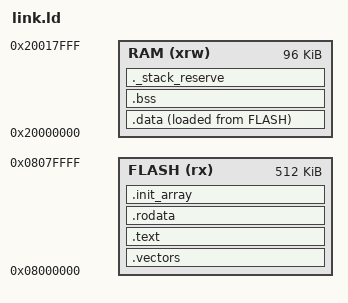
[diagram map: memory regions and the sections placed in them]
ENTRY(_reset)

_estack = ORIGIN(RAM) + LENGTH(RAM);
_Min_Stack_Size = 0x400;

MEMORY
{
  FLASH (rx)  : ORIGIN = 0x08000000, LENGTH = 512K
  RAM   (xrw) : ORIGIN = 0x20000000, LENGTH = 96K
}

SECTIONS
{
  .vectors :
  {
    . = ALIGN(4);
    KEEP(*(.vectors))
    . = ALIGN(4);
  } > FLASH

  .text :
  {
    . = ALIGN(4);
    *(.text .text*)
    *(.glue_7)
    *(.glue_7t)
    . = ALIGN(4);
    _etext = .;
  } > FLASH

  .rodata :
  {
    . = ALIGN(4);
    *(.rodata .rodata*)
    . = ALIGN(4);
  } > FLASH

  .init_array (READONLY) :
  {
    PROVIDE_HIDDEN(__init_array_start = .);
    KEEP(*(SORT(.init_array.*)))
    KEEP(*(.init_array*))
    PROVIDE_HIDDEN(__init_array_end = .);
  } > FLASH

  _sidata = LOADADDR(.data);
  .data :
  {
    . = ALIGN(4);
    _sdata = .;
    *(.data .data*)
    *(.RamFunc .RamFunc*)
    . = ALIGN(4);
    _edata = .;
  } > RAM AT > FLASH

  .bss (NOLOAD) :
  {
    . = ALIGN(4);
    _sbss = .;
    __bss_start__ = _sbss;
    *(.bss .bss*)
    *(COMMON)
    *(.ARM.__at_0x24000000)
    *(.ARM.__at_0x24000080)
    . = ALIGN(4);
    _ebss = .;
    __bss_end__ = _ebss;
  } > RAM

  ._stack_reserve (NOLOAD) :
  {
    . = ALIGN(8);
    . = . + _Min_Stack_Size;
    . = ALIGN(8);
  } > RAM

  .ARM.attributes 0 :
  {
    *(.ARM.attributes)
  }
}
